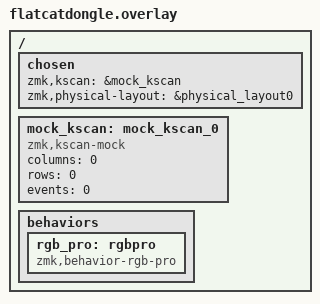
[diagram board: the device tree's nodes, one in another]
/*
 * FlatCat dongle — central with no keys.
 *
 * The dongle has no matrix of its own (mock kscan), but it must know the
 * keyboard's matrix transform and physical layout to turn the key positions
 * it receives from the peripheral into keymap bindings. Both come from the
 * same file the keyboard itself uses, so node names and contents always match.
 */

#include "../flatcat/flatcat-layouts.dtsi"

/ {
    chosen {
        zmk,kscan           = &mock_kscan;
        zmk,physical-layout = &physical_layout0;
    };

    mock_kscan: mock_kscan_0 {
        compatible = "zmk,kscan-mock";
        columns    = <0>;
        rows       = <0>;
        events     = <0>;
    };

    /* No LEDs here. The node exists so the keymap's &rgb_pro bindings resolve
       and ZMK forwards them to the keyboard BY DEVICE NAME, so the node name
       (rgbpro) must match the one in ../flatcat/flatcat.overlay. */
    behaviors {
        rgb_pro: rgbpro {
            compatible      = "zmk,behavior-rgb-pro";
            #binding-cells  = <2>;
        };
    };
};
